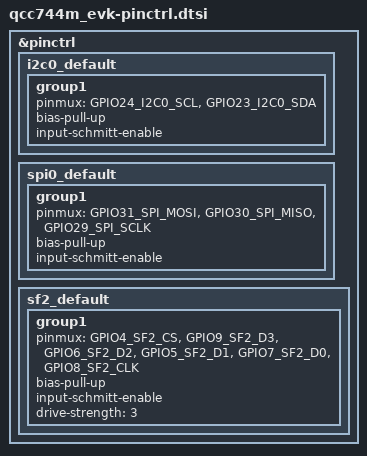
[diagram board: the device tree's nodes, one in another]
/*
 * Copyright (c) 2025-2026 MASSDRIVER EI (massdriver.space)
 *
 * SPDX-License-Identifier: Apache-2.0
 */

&pinctrl {
	i2c0_default: i2c0_default {
		group1 {
			pinmux = <GPIO24_I2C0_SCL>,
				 <GPIO23_I2C0_SDA>;
			bias-pull-up;
			input-schmitt-enable;
		};
	};

	spi0_default: spi0_default {
		group1 {
			pinmux = <GPIO31_SPI_MOSI>,
				 <GPIO30_SPI_MISO>,
				 <GPIO29_SPI_SCLK>;
			bias-pull-up;
			input-schmitt-enable;
		};
	};

	sf2_default: sf2_default {
		group1 {
			pinmux = <GPIO4_SF2_CS>,
				 <GPIO9_SF2_D3>,
				 <GPIO6_SF2_D2>,
				 <GPIO5_SF2_D1>,
				 <GPIO7_SF2_D0>,
				 <GPIO8_SF2_CLK>;
			bias-pull-up;
			input-schmitt-enable;
			drive-strength = <3>;
		};
	};
};
